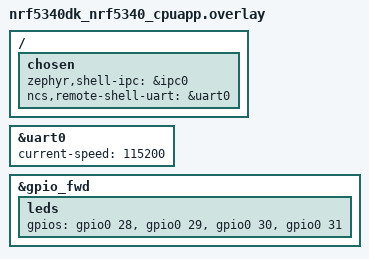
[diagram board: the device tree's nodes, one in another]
/*
 * Copyright (c) 2024 Nordic Semiconductor ASA
 *
 * SPDX-License-Identifier: LicenseRef-Nordic-5-Clause
 */

/ {
	chosen {
		zephyr,shell-ipc = &ipc0;
		ncs,remote-shell-uart = &uart0;
	};
};

&uart0 {
	status = "okay";
	current-speed = <115200>;
};

&gpio_fwd {
	status = "okay";
	leds {
		gpios = <&gpio0 28 0>,
			<&gpio0 29 0>,
			<&gpio0 30 0>,
			<&gpio0 31 0>;
		};
};
